VERSION ""

NS_ :

BS_: 500

BU_: Vector__XXX

BO_ 201 MSG_0C9: 7 Vector__XXX
 SG_ Engine_Speed : 40|16@0+ (0.25,0) [0|10000] "rpm" Vector__XXX

BO_ 241 MSG_0F1: 4 Vector__XXX
 SG_ Brake_Position : 48|8@0+ (0.392157,0) [0|100.000035] "%" Vector__XXX

BO_ 298 MSG_12A: 8 Vector__XXX
 SG_ Battery_Voltage : 16|8@0+ (0.1,3) [3|28.5] "V" Vector__XXX

BO_ 485 MSG_1E5: 8 Vector__XXX
 SG_ Steering_Angle : 40|16@0- (0.0625,0) [-2048|2047.9375] "��" Vector__XXX

BO_ 489 MSG_1E9: 8 Vector__XXX
 SG_ Yaw_Rate : 16|12@0- (0.0625,0) [-128|127.9375] "��/s" Vector__XXX

BO_ 977 MSG_3D1: 8 Vector__XXX
 SG_ Accelerator_Pedal_Position : 48|8@0+ (0.392157,0) [0|100.000035] "%" Vector__XXX

BO_ 1217 MSG_4C1: 8 Vector__XXX
 SG_ Air_Temperature : 32|8@0+ (1,-40) [-40|215] "��C" Vector__XXX
 SG_ Coolant_Temperature : 40|8@0+ (1,-40) [-40|215] "��C" Vector__XXX

BO_ 1233 MSG_4D1: 8 Vector__XXX
 SG_ Oil_Pressure : 40|8@0+ (4,0) [0|1020] "kPa" Vector__XXX
 SG_ Oil_Temperature : 48|8@0+ (1,-40) [-40|215] "��C" Vector__XXX

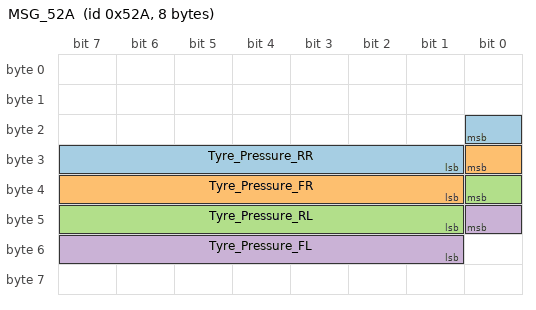
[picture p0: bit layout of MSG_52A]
BO_ 1322 MSG_52A: 8 Vector__XXX
 SG_ Tyre_Pressure_RR : 16|8@0+ (4,0) [0|1020] "kPaG" Vector__XXX
 SG_ Tyre_Pressure_FR : 24|8@0+ (4,0) [0|1020] "kPaG" Vector__XXX
 SG_ Tyre_Pressure_RL : 32|8@0+ (4,0) [0|1020] "kPaG" Vector__XXX
 SG_ Tyre_Pressure_FL : 40|8@0+ (4,0) [0|1020] "kPaG" Vector__XXX
